# soc-perf-c809403 register map
Vendor: litex
Registers are 32-bit, read-write, reset 0x0 unless marked. A register's access mark holds for its fields unless they carry their own. Offsets are from the block's base; [hi:lo] are bit positions; 'fields as' and 'values as' point back to an identical list.

## ENGINE
Base 0xF0020000
0x00 WINDOW
  [3:0] window — Selects the current register window to use
0x04 MPSTART
  [9:0] mpstart — Where to start execution
0x08 MPLEN
  [9:0] mplen — Length of the current microcode program. Thus valid code must be in the range of [mpstart, mpstart + mplen]
0x0C CONTROL
  [0] go — Writing to this puts the engine in `run` mode, and it will execute mplen microcode instructions starting at mpstart
0x10 MPRESUME
  [9:0] mpresume — Where to resume execution after a pause
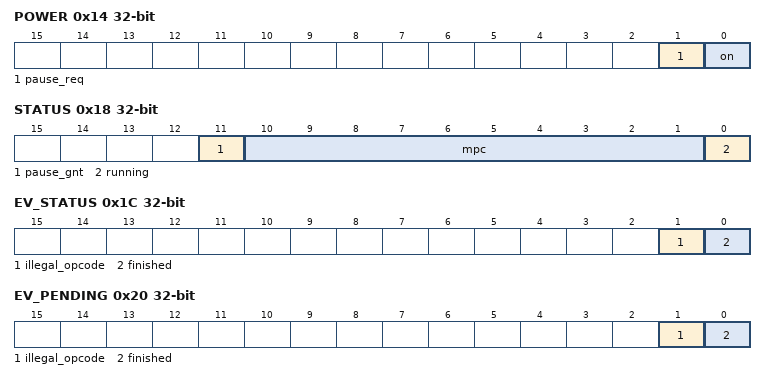
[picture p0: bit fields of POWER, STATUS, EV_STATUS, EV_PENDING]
0x14 POWER
  [1] pause_req — Writing a `1` to this block will pause execution at the next micro-op, and allow for read-out of data from RF/microcode. Must check pause_gnt to confirm the pause has happened. Used to interrupt flow for suspend/resume.
  [0] on — Writing `1` turns on the clocks to this block, `0` stops the clocks (for power savings). The handling of the clock gate is in a different module, this is just a flag to that block.
0x18 STATUS
  [11] pause_gnt — When set, the engine execution has been paused, and the RF & microcode ROM can be read out for suspend/resume
  [10:1] mpc — Current location of the microcode program counter. Mostly for debug.
  [0] running — When set, the microcode engine is running. All wishbone access to RF and microcode memory areas will stall until this bit is clear
0x1C EV_STATUS — Illegal opcode encountered
  [1] illegal_opcode — Level of the ``illegal_opcode`` event
  [0] finished — Level of the ``finished`` event
0x20 EV_PENDING — Illegal opcode encountered
  [1] illegal_opcode — Illegal opcode encountered
  [0] finished — Microcode run finished execution
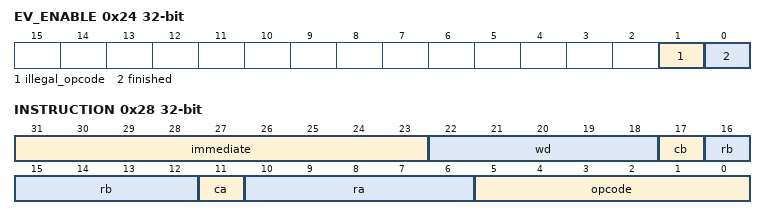
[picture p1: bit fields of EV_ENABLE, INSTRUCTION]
0x24 EV_ENABLE — Illegal opcode encountered
  [1] illegal_opcode — Write a ``1`` to enable the ``illegal_opcode`` Event
  [0] finished — Write a ``1`` to enable the ``finished`` Event
0x28 INSTRUCTION — Current instruction being executed by the engine. The format of this register exactly reflects the binary layout of an Engine instruction.
  [31:23] immediate — Used by jumps to load the next PC value
  [22:18] wd — write register
  [17] cb — set to substitute constant table value for B
  [16:12] rb — operand B read register
  [11] ca — set to substitute constant table value for A
  [10:6] ra — operand A read register
  [5:0] opcode — opcode to be executed

## JTAG
Base 0xF0021000
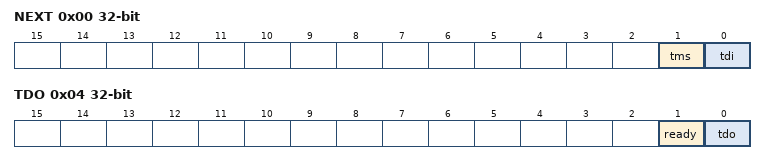
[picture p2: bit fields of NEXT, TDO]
0x00 NEXT — Next state for TDI/TMS; writing automatically clocks TCK
  [1] tms — TMS pin value
  [0] tdi — TDI pin value
0x04 TDO — TDO resulting from previous cycle
  [1] ready — JTAG machine is ready for a new cycle; also indicates TDO is valid
  [0] tdo — TDO pin value

## WDT
Base 0xF0022000
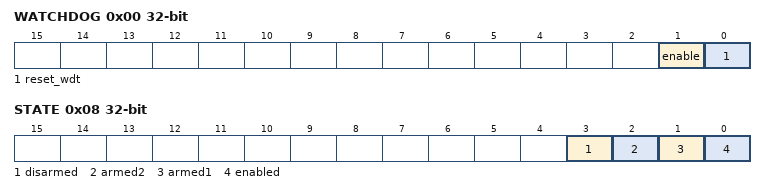
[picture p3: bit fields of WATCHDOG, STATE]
0x00 WATCHDOG
  [1] enable — Enable the watchdog timer. Cannot be disabled once enabled, except with a reset. Notably, a watchdog reset will disable the watchdog.
  [0] reset_wdt — Write to this register to reset the watchdog timer
0x04 PERIOD reset 0x135F1B40
  [31:0] period — Number of 'approximately 65MHz' CFGMCLK cycles before each reset_code must be entered. Defaults to a range of 1.67-5.00 seconds
0x08 STATE
  [3] disarmed — WDT in the disarmed state
  [2] armed2 — WDT in the armed2 state
  [1] armed1 — WDT in the armed1 state
  [0] enabled — WDT has been enabled

## USBDEV
Base 0xF0023000
0x00 USBDISABLE — When set to ``1``, USB debug core is limited by remapping all wishbone request addresses to 0x8000_0000. This does not affect the USB device core.
  [0] usbdisable
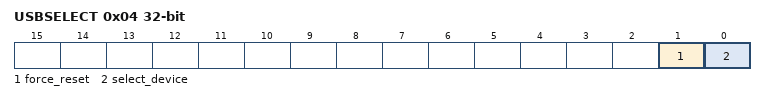
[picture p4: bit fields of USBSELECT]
0x04 USBSELECT
  [1] force_reset — When set to ``1``, the USB port is forced to a reset (disconnected) state
  [0] select_device — When set to ``1``, the spinal USB device core is selected
0x08 EV_STATUS — Interrupt from SpinalHDL core. Stays high until cleared; must read the INTERRUPT register for more detail on which interrupt caused the event.
  [0] usb — Level of the ``usb`` event
0x0C EV_PENDING — Interrupt from SpinalHDL core. Stays high until cleared; must read the INTERRUPT register for more detail on which interrupt caused the event.
  [0] usb
0x10 EV_ENABLE — Interrupt from SpinalHDL core. Stays high until cleared; must read the INTERRUPT register for more detail on which interrupt caused the event.
  [0] usb — Write a ``1`` to enable the ``usb`` Event

## D11CTIME
Base 0xF0024000
0x00 CONTROL reset 0x666
  [14:0] count — Number of 1/32768 second ticks before creating a heart beat
0x04 HEARTBEAT
  [0] beat — Set to `1` at the next `count` interval rollover since `clear` was set.

## WFI
Base 0xF0025000
0x00 WFI
  [0] wfi — Writing a `1` triggers an attempt to sleep clocks until an event happens
0x04 IGNORE_LOCKED
  [0] ignore_locked — Writing a `1` causes the reset condition for the SoC to ignore the locked state of the PLL

## EVENT_SOURCE0
Base 0xF0026000
Same registers: EVENT_SOURCE1 0xF0027000, EVENT_SOURCE2 0xF0028000, EVENT_SOURCE3 0xF0029000, EVENT_SOURCE4 0xF002A000
0x00 PERFEVENT
  [31:0] code — Code that represents the performance event. Only the lowest 2**event_width_minus_one bits are recorded. The event_width_minus_one is a global setting in the main block.

## PERFCOUNTER
Base 0xF002B000
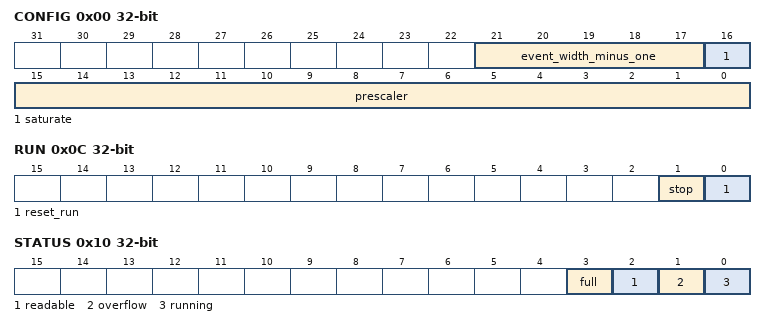
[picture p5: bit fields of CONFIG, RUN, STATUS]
0x00 CONFIG
  [21:17] event_width_minus_one — Width of the perfevent field in bits, minus 1 (so a 16-bit wide field should specify 15)
  [16] saturate — When `1`, counter will stop instead of rolling over. Must set the `saturate_limit` before setting this, otherwise it will trigger prematurely.
  [15:0] prescaler — (Number of CPU clocks + 1) per perf counter interval. 0 -> 1 clock per interval, 3-> 4 clocks per interval.
0x04 SATURATE_LIMIT1 — Bits 32-63 of `PERFCOUNTER_SATURATE_LIMIT`. Saturation limit, if selected. Set this before setting `saturate` to `1`
  [31:0] saturate_limit
0x08 SATURATE_LIMIT0 — Bits 0-31 of `PERFCOUNTER_SATURATE_LIMIT`.
  [31:0] saturate_limit
0x0C RUN
  [1] stop — When set to `1`, counter stops running. If set simultaneously with `reset_run`, the counters clear to 0 but then do not run.
  [0] reset_run — When set to `1`, counter is reset to 0 and runs
0x10 STATUS
  [3] full — If `1` indicates that the buffer is full
  [2] readable — If `1` indicates that there are events to read
  [1] overflow — Counter has overflowed since it was started
  [0] running — Counter is running when value is `1`
0x14 EVENT_INDEX
  [11:0] index — Index of the event in the FIFO. Auto-increments on read, clears on a `reset_run`
0x18 EVENT_RAW1 — Bits 32-63 of `PERFCOUNTER_EVENT_RAW`.
  [31:0] timestamp — Event code + timestamp, concatenated together per `event_width_minus_one` parameter
0x1C EVENT_RAW0 — Bits 0-31 of `PERFCOUNTER_EVENT_RAW`.
  fields as EVENT_RAW1

## IDENTIFIER_MEM
Base 0xF002C000
0x00 IDENTIFIER_MEM — 8 x 19-bit memory
  [7:0] identifier_mem
